# pktdma_gbl register map
Vendor: Texas Instruments
Peripheral module from a debugger description file (folder pktdma).
Registers are 32-bit, read-write, no defined reset value unless marked. A register's access mark holds for its fields unless they carry their own. Offsets are as the file gives them; lines under a group give offsets from that group; [hi:lo] are bit positions; {n}, {i} and the like mark numbered series; 'fields as' and 'values as' point back to an identical list; <NAME> marks a mode.

## SRIO_PKTDMA_GBL
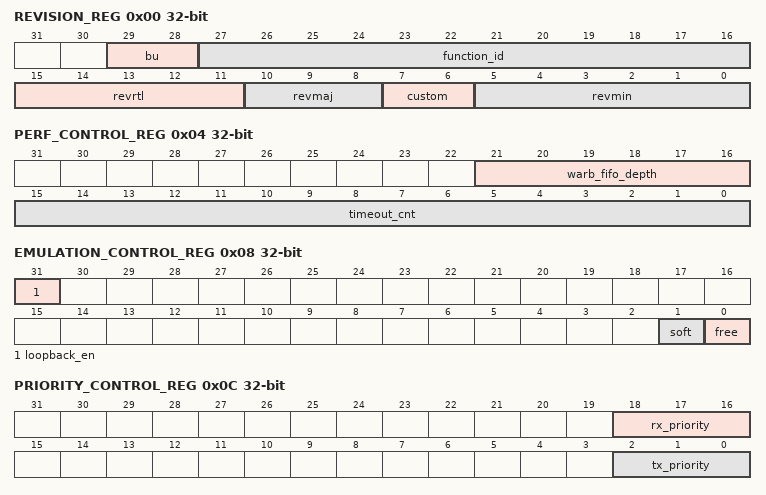
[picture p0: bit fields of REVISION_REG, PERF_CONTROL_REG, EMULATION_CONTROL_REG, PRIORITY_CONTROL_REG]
0x00 REVISION_REG ro
  [29:28] bu — Business unit
  [27:16] function_id
  [15:11] revrtl — RTL revision
  [10:8] revmaj — Major revision
  [7:6] custom
  [5:0] revmin — Minor revision
0x04 PERF_CONTROL_REG
  [21:16] warb_fifo_depth — Write-arbiter command FIFO depth
  [15:0] timeout_cnt — Specifies the minimum number of cycles to wait before attempting another RX free queue pop after a queue starvation event
0x08 EMULATION_CONTROL_REG
  [31] loopback_en — Streaming Interface loopback enable
  [1] soft
  [0] free
0x0C PRIORITY_CONTROL_REG
  [18:16] rx_priority, [2:0] tx_priority
0x10 QM_BASE_ADDRESS_REG — (1 of 4, stride 4)
  [31:0] qm_base — Provides a programmable pointer to the base address of the queues region for this instance of the Queue Manager
